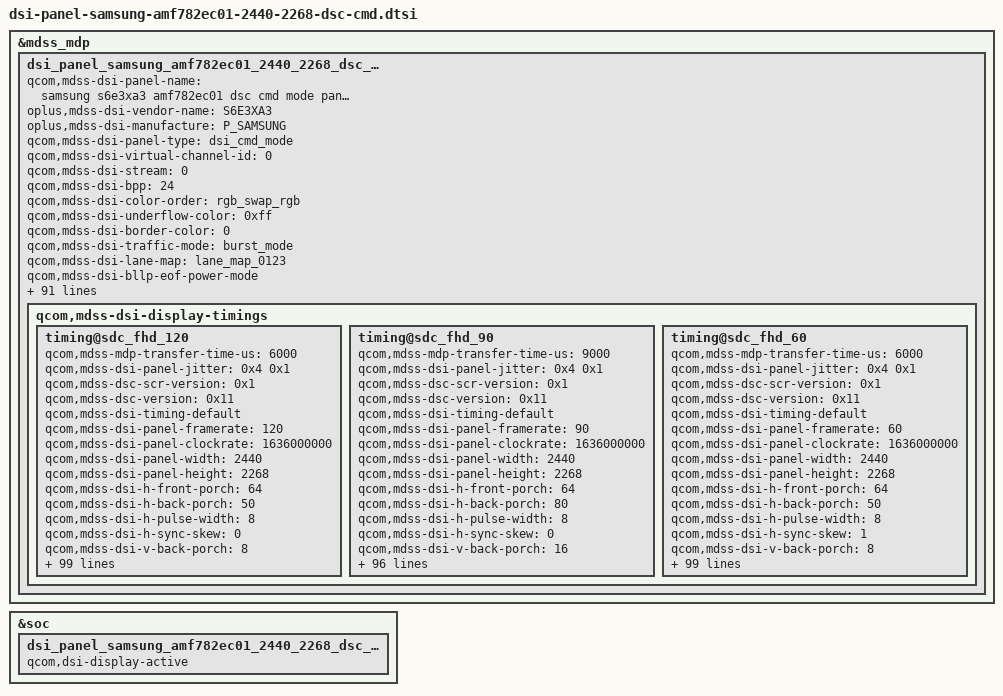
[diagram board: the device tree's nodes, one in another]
&mdss_mdp {
	dsi_panel_samsung_amf782ec01_2440_2268_dsc_cmd: qcom,mdss_dsi_panel_samsung_amf782ec01_2440_2268_dsc_cmd {
		qcom,mdss-dsi-panel-name = "samsung s6e3xa3 amf782ec01 dsc cmd mode panel";
		oplus,mdss-dsi-vendor-name = "S6E3XA3";
		oplus,mdss-dsi-manufacture = "P_SAMSUNG";
		qcom,mdss-dsi-panel-type = "dsi_cmd_mode";
		qcom,mdss-dsi-virtual-channel-id = <0>;
		qcom,mdss-dsi-stream = <0>;
		qcom,mdss-dsi-bpp = <24>;
		qcom,mdss-dsi-color-order = "rgb_swap_rgb";
		qcom,mdss-dsi-underflow-color = <0xff>;
		qcom,mdss-dsi-border-color = <0>;
		qcom,mdss-dsi-traffic-mode = "burst_mode";
		qcom,mdss-dsi-lane-map = "lane_map_0123";
		qcom,mdss-dsi-bllp-eof-power-mode;
		qcom,mdss-dsi-bllp-power-mode;
		qcom,mdss-dsi-lane-0-state;
		qcom,mdss-dsi-lane-1-state;
		qcom,mdss-dsi-lane-2-state;
		qcom,mdss-dsi-lane-3-state;
		qcom,mdss-dsi-dma-trigger = "trigger_sw";
		qcom,mdss-loading-effect;
		qcom,mdss-dsi-mdp-trigger = "none";
		qcom,mdss-dsi-reset-sequence = <1 10>, <0 5>, <1 10>;
		qcom,mdss-dsi-te-pin-select = <1>;
		qcom,mdss-dsi-te-dcs-command = <1>;
		qcom,mdss-pan-physical-width-dimension = <145>;
		qcom,mdss-pan-physical-height-dimension = <135>;
		qcom,mdss-dsi-init-delay-us = <1000>;
		qcom,mdss-dsi-te-check-enable;
		qcom,mdss-dsi-te-using-te-pin;
//		qcom,mdss-dsi-lp11-init;
		qcom,mdss-dsi-wr-mem-start = <0x2c>;
		qcom,mdss-dsi-wr-mem-continue = <0x3c>;
		qcom,mdss-dsi-panel-jitter = <0x4 0x1>;
		qcom,mdss-dsc-scr-version = <0x1>;
		qcom,mdss-bl-high2bit;
		/* HDR Setting */
		qcom,mdss-dsi-panel-hdr-enabled;
		qcom,mdss-dsi-panel-hdr-color-primaries = <15635 16450 34000 16000 13250 34500 7500 3000>;
		qcom,mdss-dsi-panel-peak-brightness = <5400000>;
		qcom,mdss-dsi-panel-average-brightness = <2000000>;
		qcom,mdss-dsi-panel-blackness-level = <4000>;
//		qcom,spr-pack-type = "pentile";

		qcom,dynamic-mode-switch-enabled;
		qcom,dynamic-mode-switch-type = "dynamic-resolution-switch-immediate";
		qcom,mdss-dsi-display-timings {
			timing@sdc_fhd_120{
				qcom,mdss-mdp-transfer-time-us = <6000>;
				qcom,mdss-dsi-panel-jitter = <0x4 0x1>;
				qcom,mdss-dsc-scr-version = <0x1>;
				qcom,mdss-dsc-version = <0x11>;
				qcom,mdss-dsi-timing-default;
				qcom,mdss-dsi-panel-framerate = <120>;
				qcom,mdss-dsi-panel-clockrate = <1636000000>;
				qcom,mdss-dsi-panel-width = <2440>;
				qcom,mdss-dsi-panel-height = <2268>;

				qcom,mdss-dsi-h-front-porch = <64>;
				qcom,mdss-dsi-h-back-porch = <50>;
				qcom,mdss-dsi-h-pulse-width = <8>;
				qcom,mdss-dsi-h-sync-skew = <0>;
				qcom,mdss-dsi-v-back-porch = <8>;
				qcom,mdss-dsi-v-front-porch = <2>;
				qcom,mdss-dsi-v-pulse-width = <2>;
				qcom,mdss-dsi-h-sync-pulse = <0>;

				qcom,mdss-dsi-h-left-border = <0>;
				qcom,mdss-dsi-h-right-border = <0>;
				qcom,mdss-dsi-v-top-border = <0>;
				qcom,mdss-dsi-v-bottom-border = <0>;

				/* Apollo vsync config, need to measure TE signal */
				//oplus,apollo-panel-vsync-width = <13000>;
				//oplus,apollo-panel-vsync-period = <16600>;

				oplus,fod-on-vblank = <0>;
				oplus,fod-off-vblank = <0>;
				//qcom,mdss-dsi-panel-read-register-open-command = [
				//	39 01 00 00 00 00 03 F0 5A 5A
				//	];
				qcom,mdss-dsi-panel-id1-command = [
					06 01 00 00 00 00 01 E9
					];
				//qcom,mdss-dsi-panel-read-register-close-command = [
				//	39 01 00 00 00 00 03 F0 A5 A5
				//	];
				qcom,mdss-dsi-timing-switch-command = [
					/*2c enable 3c disable*/
					39 00 00 40 00 00 03 F0 5A 5A
					39 00 00 40 00 00 04 B0 00 80 BD
					15 00 00 40 00 00 02 BD 16
					39 00 00 00 00 00 03 F0 A5 A5
					/*Frame rate=120Hz*/
					39 00 00 40 00 00 03 F0 5A 5A
					15 00 00 40 00 00 02 F2 01
					15 00 00 40 00 00 02 60 00
					15 00 00 40 00 00 02 F7 0F
					39 00 00 00 00 00 03 F0 A5 A5
					/*Manual 120Hz*/
					39 00 00 40 00 00 03 F0 5A 5A
					15 00 00 40 00 00 02 BD E1
					15 00 00 40 00 00 02 60 00
					15 00 00 40 00 00 02 F7 0F
					39 00 00 00 00 00 03 F0 A5 A5
					/*Fixed Te*/
					39 00 00 40 00 00 03 F0 5A 5A
					39 00 00 40 00 00 11 B9 51 41 00 00 00 00 00 00 08 F0 00 0F 08 F0 00 0F
					15 00 00 40 00 00 02 B9 51
					15 00 00 40 00 00 02 F7 0F
					39 00 00 00 00 00 03 F0 A5 A5
					/*Dynamic Single Te*/
					39 00 00 40 00 00 03 F0 5A 5A
					39 00 00 40 00 00 04 B0 00 44 F2
					15 00 00 40 00 00 02 F2 0D
					39 00 00 40 00 00 04 B0 00 01 B9
					15 00 00 40 00 00 02 B9 11
					15 00 00 40 00 00 02 F7 0F
					39 00 00 00 00 00 03 F0 A5 A5
					];
				qcom,mdss-dsi-on-command=[
					/*DSC Setting*/
					39 00 00 40 00 00 5A 9E 11 00 00 89 30 80 08 DC 09 88 00 3F 04 C4 04 C4 02 00 03 63 00 20 08 8B 00 10 00 0C 01 8D 00 B7 18 00 10 F0 03 0C 20 00 06 0B 0B 33 0E 1C 2A 38 46 54 62 69 70 77 79 7B 7D 7E 01 02 01 00 09 40 09 BE 19 FC 19 FA 19 F8 1A 38 1A 78 1A B6 2A F6 2B 34 2B 74 3B 74 6B F4 00
					15 00 00 00 00 00 02 9D 01
					/*sleep out*/
					05 00 00 00 78 00 01 11
					/*TE ON*/
					15 00 00 00 00 00 02 35 00
					/*CASET/PASET SETING*/
					39 00 00 40 00 00 05 2A 00 00 09 87
					39 00 00 00 00 00 05 2B 00 00 08 DB
					/*Pentile Setting*/
					39 00 00 40 00 00 03 F0 5A 5A
					39 00 00 40 00 00 04 B0 00 A2 92
					39 00 00 40 00 00 07 92 0A 0A D8 D8 C0 C0
					15 00 00 40 00 00 02 F7 0F
					39 00 00 00 00 00 03 F0 A5 A5
					/* ERR_FG_Setting */
					39 00 00 40 00 00 03 F0 5A 5A
					15 00 00 40 00 00 02 E5 15
					39 00 00 40 00 00 04 B0 00 02 ED
					15 00 00 40 00 00 02 ED 60
					39 00 00 40 00 00 04 B0 00 59 F4
					15 00 00 40 00 00 02 F4 10
					39 00 00 40 00 00 03 ED 00 51
					39 00 00 00 00 00 03 F0 A5 A5
					/*Dimming Setting*/
					39 00 00 40 00 00 03 F0 5A 5A
					15 00 00 40 00 00 02 53 20
					15 00 00 40 00 00 02 F7 0F
					39 00 00 00 00 00 03 F0 A5 A5
					/*2c enable 3c disable*/
					39 00 00 40 00 00 03 F0 5A 5A
					39 00 00 40 00 00 04 B0 00 80 BD
					15 00 00 40 00 00 02 BD 16
					39 00 00 00 00 00 03 F0 A5 A5
					/*Frame rate=120Hz*/
					39 00 00 40 00 00 03 F0 5A 5A
					15 00 00 40 00 00 02 F2 01
					15 00 00 40 00 00 02 60 00
					15 00 00 40 00 00 02 F7 0F
					39 00 00 00 00 00 03 F0 A5 A5
					/*Manual 120Hz*/
					39 00 00 40 00 00 03 F0 5A 5A
					15 00 00 40 00 00 02 BD E1
					15 00 00 40 00 00 02 60 00
					15 00 00 40 00 00 02 F7 0F
					39 00 00 00 00 00 03 F0 A5 A5
					/*Fixed Te*/
					39 00 00 40 00 00 03 F0 5A 5A
					39 00 00 40 00 00 11 B9 51 41 00 00 00 00 00 00 08 F0 00 0F 08 F0 00 0F
					15 00 00 40 00 00 02 B9 51
					15 00 00 40 00 00 02 F7 0F
					39 00 00 00 00 00 03 F0 A5 A5
					/*Dynamic Single Te*/
					39 00 00 40 00 00 03 F0 5A 5A
					39 00 00 40 00 00 04 B0 00 44 F2
					15 00 00 40 00 00 02 F2 0D
					39 00 00 40 00 00 04 B0 00 01 B9
					15 00 00 40 00 00 02 B9 11
					15 00 00 40 00 00 02 F7 0F
					39 00 00 00 00 00 03 F0 A5 A5
					/*display on*/
					05 00 00 00 00 00 01 29
				];

				qcom,mdss-dsi-panel-info-switch-page-command = [
					/*read panel info switch page 01*/
					39 00 00 00 00 00 06 F0 55 AA 52 08 01
				];
				qcom,mdss-dsi-default-switch-page-command = [
					/*switch default page*/
					39 00 00 00 00 00 06 F0 55 AA 52 08 00
				];
				qcom,mdss-dsi-qsync-on-commands = [
					/* SDC Auto On */
				];
				qcom,mdss-dsi-qsync-off-commands = [
					/* SDC Auto Off */
				];
				qcom,mdss-dsi-qsync-min-fps-0-command = [
					/* SDC Auto Off */
					39 00 00 40 00 00 03 F0 5A 5A
					15 00 00 40 00 00 02 BD E1
					15 00 00 40 00 00 02 60 00
					15 00 00 40 00 00 02 F7 0F
					39 00 00 00 00 00 03 F0 A5 A5
				];
				qcom,mdss-dsi-qsync-min-fps-1-command = [
					/* SDC Auto On */
				];

				qcom,mdss-dsi-post-on-backlight = [
					/* Display On */
					05 00 00 00 00 00 01 29
				];
				qcom,mdss-dsi-off-command=[
					05 00 00 00 14 00 01 28
					05 00 00 00 78 00 01 10
				];
				qcom,mdss-dsi-lp1-command = [
					/* Panel OFF */
					05 00 00 00 09 00 01 28
					/* AOD Mode ON Setting */
					39 00 00 40 00 00 03 F0 5A 5A
					39 00 00 40 00 00 04 B0 00 52 64
					39 00 00 40 00 00 07 64 01 03 29 0B 03 2A
					15 00 00 40 00 00 02 53 24
					39 00 00 40 00 00 03 51 07 FF
					15 00 00 40 00 00 02 F7 0F
					39 00 00 00 00 00 03 F0 A5 A5
				];
				qcom,mdss-dsi-nolp-command = [
					/* Panel OFF */
					05 00 00 00 00 00 01 28
					/* AOD Mode OFF Setting */
					39 00 00 40 00 00 03 F0 5A 5A
					39 00 00 40 00 00 04 B0 00 52 64
					15 00 00 40 00 00 02 64 00
					15 00 00 40 00 00 02 53 20
					39 00 00 40 00 00 03 51 00 00
					15 00 00 40 00 00 02 F7 0F
					39 00 00 00 22 00 03 F0 A5 A5
					/* Panel ON */
					05 00 00 00 00 00 01 29
				];
				qcom,mdss-dsi-hbm-off-command = [
					39 00 00 40 00 00 03 F0 5A 5A
					39 00 00 40 00 00 03 51 08 00
					39 00 00 00 00 00 03 F0 A5 A5
				];
				qcom,mdss-dsi-hbm-on-command = [
					39 00 00 40 00 00 03 F0 5A 5A
					39 00 00 40 00 00 03 51 0F 00
					39 00 00 00 00 00 03 F0 A5 A5
				];
				qcom,mdss-dsi-aod-high-mode-command = [
					/* AOD 50nit */
					15 00 00 40 00 00 02 6F 04
					39 00 00 00 00 00 03 51 07 FF
				];
				qcom,mdss-dsi-aod-low-mode-command = [
					/* AOD 10nit */
					15 00 00 40 00 00 02 6F 04
					39 00 00 00 00 00 03 51 03 8A
				];
				//qcom,mdss-dsi-esd-switch-page-command = [
				//	39 00 00 00 00 00 05 FF AA 55 A5 81
				//	15 00 00 00 00 00 02 6F 0F
				//];
				qcom,mdss-dsi-bl-3plus-command = [
					/*3plus 51Hey > 0x643*/
				];
				qcom,mdss-dsi-bl-16plus-command = [
					/*16plus 51Hey <= 0x643*/
				];
				qcom,mdss-dsi-temperature-compensation-command = [
				];
				qcom,mdss-dsi-loading-effect-1-command = [
					/* Laoding On 100% */
					39 00 00 40 00 00 03 F0 5A 5A
					39 00 00 40 00 00 04 B0 00 AF 93
					15 00 00 40 00 00 02 93 A3
					39 00 00 40 00 00 04 B0 00 B0 93
					39 00 00 40 00 00 27 93 FC 0B 92 80 01 FF 00 8C FF 00 FF 35 58 6D 06 06 05 18 19 16 20 22 1E 26 28 24 29 2B 26 3D 8D 86 E8 20 00 00 08 54
					39 00 00 40 00 00 04 B0 00 39 94
					39 00 00 40 00 00 27 94 E2 00 00 00 82 46 24 80 00 00 00 00 FF 90 00 00 01 00 00 00 00 00 00 00 00 00 00 00 00 00 00 00 00 00 00 00 00 00
					39 00 00 40 00 00 04 B0 00 41 94
					39 00 00 40 00 00 07 94 00 00 00 00 FF 90
					39 00 00 00 00 00 03 F0 A5 A5
				];
				qcom,mdss-dsi-loading-effect-2-command = [
					/* Laoding On 110% */
					39 00 00 40 00 00 03 F0 5A 5A
					39 00 00 40 00 00 04 B0 00 AF 93
					15 00 00 40 00 00 02 93 A3
					39 00 00 40 00 00 04 B0 00 B0 93
					39 00 00 40 00 00 27 93 FC 0B 92 80 01 FF 00 8C FF 00 FF 35 58 6D 06 06 05 18 19 16 20 22 1E 26 28 24 29 2B 26 3D 8D 86 E8 20 00 00 08 54
					39 00 00 40 00 00 04 B0 00 39 94
					39 00 00 40 00 00 27 94 E2 00 00 00 82 46 24 80 00 00 00 00 FF 90 00 00 01 00 00 00 00 00 00 00 00 00 00 00 00 00 00 00 00 00 00 00 00 00
					39 00 00 40 00 00 04 B0 00 41 94
					39 00 00 40 00 00 07 94 9B 7C 7C 63 FF 90
					39 00 00 00 00 00 03 F0 A5 A5
				];
				qcom,mdss-dsi-loading-effect-3-command = [
				];
				qcom,mdss-dsi-loading-effect-4-command = [
				];
				qcom,mdss-dsi-loading-effect-off-command = [
					39 00 00 40 00 00 03 F0 5A 5A
					39 00 00 40 00 00 04 B0 00 AF 93
					15 00 00 40 00 00 02 93 83
					39 00 00 00 00 00 03 F0 A5 A5
				];
				qcom,mdss-dsi-loading-effect-1-command-state = "dsi_hs_mode";
				qcom,mdss-dsi-loading-effect-2-command-state = "dsi_hs_mode";
				qcom,mdss-dsi-loading-effect-3-command-state = "dsi_hs_mode";
				qcom,mdss-dsi-loading-effect-4-command-state = "dsi_hs_mode";
				qcom,mdss-dsi-loading-effect-off-command-state = "dsi_hs_mode";
				qcom,mdss-dsi-timing-switch-command-state = "dsi_hs_mode";
				qcom,mdss-dsi-on-command-state = "dsi_lp_mode";
				qcom,mdss-dsi-off-command-state = "dsi_hs_mode";
				qcom,mdss-dsi-hbm-on-command-state = "dsi_lp_mode";
				qcom,mdss-dsi-hbm-off-command-state = "dsi_lp_mode";
				qcom,mdss-dsi-bl-16plus-command-state = "dsi_hs_mode";
				qcom,mdss-dsi-bl-3plus-command-state = "dsi_hs_mode";
				qcom,mdss-dsi-temperature-compensation-command-state = "dsi_hs_mode";
				qcom,mdss-dsi-panel-info-switch-page-command-state = "dsi_lp_mode";
				qcom,mdss-dsi-default-switch-page-command-state = "dsi_lp_mode";

				qcom,mdss-dsi-qsync-min-fps-0-command-state = "dsi_hs_mode";
				qcom,mdss-dsi-qsync-min-fps-1-command-state = "dsi_hs_mode";

				qcom,lm-split = <1220 1220>;
				qcom,compression-mode = "dsc";
				qcom,mdss-dsc-encoders = <2>;
				qcom,mdss-dsc-slice-height = <63>;
				qcom,mdss-dsc-slice-width = <1220>;
				qcom,mdss-dsc-slice-per-pkt = <2>;
				qcom,mdss-dsc-bit-per-component = <8>;
				qcom,mdss-dsc-bit-per-pixel = <8>;
				qcom,mdss-dsc-block-prediction-enable;
				qcom,mdss-dsi-panel-id1-command-state = "dsi_lp_mode";
			};
			timing@sdc_fhd_90{
				qcom,mdss-mdp-transfer-time-us = <9000>;
				qcom,mdss-dsi-panel-jitter = <0x4 0x1>;
				qcom,mdss-dsc-scr-version = <0x1>;
				qcom,mdss-dsc-version = <0x11>;
				qcom,mdss-dsi-timing-default;
				qcom,mdss-dsi-panel-framerate = <90>;
				qcom,mdss-dsi-panel-clockrate = <1636000000>;
				qcom,mdss-dsi-panel-width = <2440>;
				qcom,mdss-dsi-panel-height = <2268>;

				qcom,mdss-dsi-h-front-porch = <64>;
				qcom,mdss-dsi-h-back-porch = <80>;
				qcom,mdss-dsi-h-pulse-width = <8>;
				qcom,mdss-dsi-h-sync-skew = <0>;
				qcom,mdss-dsi-v-back-porch = <16>;
				qcom,mdss-dsi-v-front-porch = <10>;
				qcom,mdss-dsi-v-pulse-width = <2>;
				qcom,mdss-dsi-h-sync-pulse = <0>;

				qcom,mdss-dsi-h-left-border = <0>;
				qcom,mdss-dsi-h-right-border = <0>;
				qcom,mdss-dsi-v-top-border = <0>;
				qcom,mdss-dsi-v-bottom-border = <0>;

				/* Apollo vsync config, need to measure TE signal */
				//oplus,apollo-panel-vsync-width = <13000>;
				//oplus,apollo-panel-vsync-period = <16600>;

				oplus,fod-on-vblank = <0>;
				oplus,fod-off-vblank = <0>;
				//qcom,mdss-dsi-panel-read-register-open-command = [
				//	39 00 00 00 00 00 03 F0 5A 5A
				//	];
				qcom,mdss-dsi-panel-id1-command = [
					06 00 00 00 00 00 01 E9
					];
				//qcom,mdss-dsi-panel-read-register-close-command = [
				//	39 00 00 00 00 00 03 F0 A5 A5
				//	];
				qcom,mdss-dsi-timing-switch-command = [
					/* Frequence Transition */
					39 00 00 40 00 00 03 F0 5A 5A
					15 00 00 40 00 00 02 B9 11
					15 00 00 40 00 00 02 F2 01
					15 00 00 40 00 00 02 60 10
					15 00 00 40 00 00 02 F7 0F
					39 00 00 00 00 00 03 F0 A5 A5
					];
				qcom,mdss-dsi-on-command=[
					/*DSC Setting*/
					39 00 00 40 00 00 5A 9E 11 00 00 89 30 80 08 DC 09 88 00 3F 04 C4 04 C4 02 00 03 63 00 20 08 8B 00 10 00 0C 01 8D 00 B7 18 00 10 F0 03 0C 20 00 06 0B 0B 33 0E 1C 2A 38 46 54 62 69 70 77 79 7B 7D 7E 01 02 01 00 09 40 09 BE 19 FC 19 FA 19 F8 1A 38 1A 78 1A B6 2A F6 2B 34 2B 74 3B 74 6B F4 00
					15 00 00 00 00 00 02 9D 01
					/*sleep out*/
					05 00 00 00 78 00 01 11
					/*TE ON*/
					15 00 00 00 00 00 02 35 00
					/*CASET/PASET SETING*/
					39 00 00 40 00 00 05 2A 00 00 09 87
					39 00 00 00 00 00 05 2B 00 00 08 DB
					/*Pentile Setting*/
					39 00 00 40 00 00 03 F0 5A 5A
					39 00 00 40 00 00 04 B0 00 A2 92
					39 00 00 40 00 00 07 92 0A 0A D8 D8 C0 C0
					15 00 00 40 00 00 02 F7 0F
					39 00 00 00 00 00 03 F0 A5 A5
					/* ERR_FG_Setting */
					39 00 00 40 00 00 03 F0 5A 5A
					15 00 00 40 00 00 02 E5 15
					39 00 00 40 00 00 04 B0 00 02 ED
					15 00 00 40 00 00 02 ED 60
					39 00 00 40 00 00 04 B0 00 59 F4
					15 00 00 40 00 00 02 F4 10
					39 00 00 40 00 00 03 ED 00 51
					39 00 00 00 00 00 03 F0 A5 A5
					/*Dimming Setting*/
					39 00 00 40 00 00 03 F0 5A 5A
					15 00 00 40 00 00 02 53 20
					15 00 00 40 00 00 02 F7 0F
					39 00 00 00 00 00 03 F0 A5 A5
					/*Frame rate=90Hz*/
					39 00 00 40 00 00 03 F0 5A 5A
					15 00 00 40 00 00 02 B9 11
					15 00 00 40 00 00 02 F2 01
					15 00 00 40 00 00 02 60 10
					15 00 00 40 00 00 02 F7 0F
					39 00 00 00 00 00 03 F0 A5 A5
					/*display on*/
					05 00 00 00 00 00 01 29
				];

				qcom,mdss-dsi-panel-info-switch-page-command = [
					/*read panel info switch page 01*/
					39 00 00 00 00 00 06 F0 55 AA 52 08 01
				];
				qcom,mdss-dsi-default-switch-page-command = [
					/*switch default page*/
					39 00 00 00 00 00 06 F0 55 AA 52 08 00
				];
				qcom,mdss-dsi-qsync-on-commands = [
					/* SDC Auto On */
				];
				qcom,mdss-dsi-qsync-off-commands = [
					/* SDC Auto Off */
				];
				qcom,mdss-dsi-qsync-min-fps-0-command = [
					/* SDC Auto Off */
				];
				qcom,mdss-dsi-qsync-min-fps-1-command = [
					/* SDC Auto On */
				];

				qcom,mdss-dsi-post-on-backlight = [
					/* Display On */
					05 00 00 00 00 00 01 29
				];
				qcom,mdss-dsi-off-command=[
					05 00 00 00 14 00 01 28
					05 00 00 00 78 00 01 10
				];
				qcom,mdss-dsi-lp1-command = [
					/* Panel OFF */
					05 00 00 00 0B 00 01 28
					/* AOD Mode ON Setting */
					39 00 00 40 00 00 03 F0 5A 5A
					39 00 00 40 00 00 04 B0 00 52 64
					39 00 00 40 00 00 07 64 01 03 29 0B 03 2A
					15 00 00 40 00 00 02 53 24
					39 00 00 40 00 00 03 51 07 FF
					15 00 00 40 00 00 02 F7 0F
					39 00 00 00 00 00 03 F0 A5 A5
				];
				qcom,mdss-dsi-nolp-command = [
					/* Panel OFF */
					05 00 00 00 00 00 01 28
					/* AOD Mode OFF Setting */
					39 00 00 40 00 00 03 F0 5A 5A
					39 00 00 40 00 00 04 B0 00 52 64
					15 00 00 40 00 00 02 64 00
					15 00 00 40 00 00 02 53 20
					39 00 00 40 00 00 03 51 00 00
					15 00 00 40 00 00 02 F7 0F
					39 00 00 00 22 00 03 F0 A5 A5
					/* Panel ON */
					05 00 00 00 00 00 01 29
				];
				qcom,mdss-dsi-hbm-off-command = [
					39 00 00 40 00 00 03 F0 5A 5A
					39 00 00 40 00 00 03 51 08 00
					39 00 00 00 00 00 03 F0 A5 A5
				];
				qcom,mdss-dsi-hbm-on-command = [
					39 00 00 40 00 00 03 F0 5A 5A
					39 00 00 40 00 00 03 51 0F 00
					39 00 00 00 00 00 03 F0 A5 A5
				];
				qcom,mdss-dsi-aod-high-mode-command = [
					/* AOD 50nit */
					15 00 00 40 00 00 02 6F 04
					39 00 00 00 00 00 03 51 07 FF
				];
				qcom,mdss-dsi-aod-low-mode-command = [
					/* AOD 10nit */
					15 00 00 40 00 00 02 6F 04
					39 00 00 00 00 00 03 51 03 8A
				];
				//qcom,mdss-dsi-esd-switch-page-command = [
				//	39 00 00 00 00 00 05 FF AA 55 A5 81
				//	15 00 00 00 00 00 02 6F 0F
				//];
				qcom,mdss-dsi-bl-3plus-command = [
					/*3plus 51Hey > 0x643*/
					39 00 00 00 00 00 06 F0 55 AA 52 08 00
					39 00 00 00 00 00 02 6F 12
					39 00 00 00 00 00 02 B2 03
				];
				qcom,mdss-dsi-bl-16plus-command = [
					/*16plus 51Hey <= 0x643*/
					39 00 00 00 00 00 06 F0 55 AA 52 08 00
					39 00 00 00 00 00 02 6F 12
					39 00 00 00 00 00 02 B2 0F
				];
				qcom,mdss-dsi-temperature-compensation-command = [
				];
				qcom,mdss-dsi-loading-effect-1-command = [
					/* Laoding On 100% */
					39 00 00 40 00 00 03 F0 5A 5A
					39 00 00 40 00 00 04 B0 00 AF 93
					15 00 00 40 00 00 02 93 A3
					39 00 00 40 00 00 04 B0 00 B0 93
					39 00 00 40 00 00 27 93 FC 0B 92 80 01 FF 00 8C FF 00 FF 35 58 6D 06 06 05 18 19 16 20 22 1E 26 28 24 29 2B 26 3D 8D 86 E8 20 00 00 08 54
					39 00 00 40 00 00 04 B0 00 39 94
					39 00 00 40 00 00 27 94 E2 00 00 00 82 46 24 80 00 00 00 00 FF 90 00 00 01 00 00 00 00 00 00 00 00 00 00 00 00 00 00 00 00 00 00 00 00 00
					39 00 00 40 00 00 04 B0 00 41 94
					39 00 00 40 00 00 07 94 00 00 00 00 FF 90
					39 00 00 00 00 00 03 F0 A5 A5
				];
				qcom,mdss-dsi-loading-effect-2-command = [
					/* Laoding On 110% */
					39 00 00 40 00 00 03 F0 5A 5A
					39 00 00 40 00 00 04 B0 00 AF 93
					15 00 00 40 00 00 02 93 A3
					39 00 00 40 00 00 04 B0 00 B0 93
					39 00 00 40 00 00 27 93 FC 0B 92 80 01 FF 00 8C FF 00 FF 35 58 6D 06 06 05 18 19 16 20 22 1E 26 28 24 29 2B 26 3D 8D 86 E8 20 00 00 08 54
					39 00 00 40 00 00 04 B0 00 39 94
					39 00 00 40 00 00 27 94 E2 00 00 00 82 46 24 80 00 00 00 00 FF 90 00 00 01 00 00 00 00 00 00 00 00 00 00 00 00 00 00 00 00 00 00 00 00 00
					39 00 00 40 00 00 04 B0 00 41 94
					39 00 00 40 00 00 07 94 9B 7C 7C 63 FF 90
					39 00 00 00 00 00 03 F0 A5 A5
				];
				qcom,mdss-dsi-loading-effect-3-command = [
				];
				qcom,mdss-dsi-loading-effect-4-command = [
				];
				qcom,mdss-dsi-loading-effect-off-command = [
					39 00 00 40 00 00 03 F0 5A 5A
					39 00 00 40 00 00 04 B0 00 AF 93
					15 00 00 40 00 00 02 93 83
					39 00 00 00 00 00 03 F0 A5 A5
				];
				qcom,mdss-dsi-loading-effect-1-command-state = "dsi_hs_mode";
				qcom,mdss-dsi-loading-effect-2-command-state = "dsi_hs_mode";
				qcom,mdss-dsi-loading-effect-3-command-state = "dsi_hs_mode";
				qcom,mdss-dsi-loading-effect-4-command-state = "dsi_hs_mode";
				qcom,mdss-dsi-loading-effect-off-command-state = "dsi_hs_mode";
				qcom,mdss-dsi-timing-switch-command-state = "dsi_hs_mode";
				qcom,mdss-dsi-on-command-state = "dsi_lp_mode";
				qcom,mdss-dsi-off-command-state = "dsi_hs_mode";
				qcom,mdss-dsi-hbm-on-command-state = "dsi_lp_mode";
				qcom,mdss-dsi-hbm-off-command-state = "dsi_lp_mode";
				qcom,mdss-dsi-bl-16plus-command-state = "dsi_hs_mode";
				qcom,mdss-dsi-bl-3plus-command-state = "dsi_hs_mode";
				qcom,mdss-dsi-temperature-compensation-command-state = "dsi_hs_mode";
				qcom,mdss-dsi-panel-info-switch-page-command-state = "dsi_lp_mode";
				qcom,mdss-dsi-default-switch-page-command-state = "dsi_lp_mode";

				qcom,lm-split = <1220 1220>;
				qcom,compression-mode = "dsc";
				qcom,mdss-dsc-encoders = <2>;
				qcom,mdss-dsc-slice-height = <63>;
				qcom,mdss-dsc-slice-width = <1220>;
				qcom,mdss-dsc-slice-per-pkt = <2>;
				qcom,mdss-dsc-bit-per-component = <8>;
				qcom,mdss-dsc-bit-per-pixel = <8>;
				qcom,mdss-dsc-block-prediction-enable;
				qcom,mdss-dsi-panel-id1-command-state = "dsi_lp_mode";
			};
			timing@sdc_fhd_60{
				qcom,mdss-mdp-transfer-time-us = <6000>;
				qcom,mdss-dsi-panel-jitter = <0x4 0x1>;
				qcom,mdss-dsc-scr-version = <0x1>;
				qcom,mdss-dsc-version = <0x11>;
				qcom,mdss-dsi-timing-default;
				qcom,mdss-dsi-panel-framerate = <60>;
				qcom,mdss-dsi-panel-clockrate = <1636000000>;
				qcom,mdss-dsi-panel-width = <2440>;
				qcom,mdss-dsi-panel-height = <2268>;

				qcom,mdss-dsi-h-front-porch = <64>;
				qcom,mdss-dsi-h-back-porch = <50>;
				qcom,mdss-dsi-h-pulse-width = <8>;
				qcom,mdss-dsi-h-sync-skew = <1>;
				qcom,mdss-dsi-v-back-porch = <8>;
				qcom,mdss-dsi-v-front-porch = <2>;
				qcom,mdss-dsi-v-pulse-width = <2>;
				qcom,mdss-dsi-h-sync-pulse = <0>;

				qcom,mdss-dsi-h-left-border = <0>;
				qcom,mdss-dsi-h-right-border = <0>;
				qcom,mdss-dsi-v-top-border = <0>;
				qcom,mdss-dsi-v-bottom-border = <0>;

				/* Apollo vsync config, need to measure TE signal */
				//oplus,apollo-panel-vsync-width = <13000>;
				//oplus,apollo-panel-vsync-period = <16600>;

				oplus,fod-on-vblank = <0>;
				oplus,fod-off-vblank = <0>;
				//qcom,mdss-dsi-panel-read-register-open-command = [
				//	39 01 00 00 00 00 03 F0 5A 5A
				//	];
				qcom,mdss-dsi-panel-id1-command = [
					06 01 00 00 00 00 01 E9
					];
				//qcom,mdss-dsi-panel-read-register-close-command = [
				//	39 01 00 00 00 00 03 F0 A5 A5
				//	];
				qcom,mdss-dsi-timing-switch-command = [
					/*2c enable 3c disable*/
					39 00 00 40 00 00 03 F0 5A 5A
					39 00 00 40 00 00 04 B0 00 80 BD
					15 00 00 40 00 00 02 BD 16
					39 00 00 00 00 00 03 F0 A5 A5
					/*Manual 60Hz*/
					39 00 00 40 00 00 03 F0 5A 5A
					15 00 00 40 00 00 02 F2 01
					15 00 00 40 00 00 02 60 00
					15 00 00 40 00 00 02 BD E1
					15 00 00 40 00 00 02 60 01
					15 00 00 40 00 00 02 F7 0F
					39 00 00 00 00 00 03 F0 A5 A5
					/*Fixed Te 60HZ*/
					39 00 00 40 00 00 03 F0 5A 5A
					39 00 00 40 00 00 11 B9 51 41 01 00 00 00 00 00 08 F0 00 0F 08 F0 00 0F
					15 00 00 40 00 00 02 B9 51
					15 00 00 40 00 00 02 F7 0F
					39 00 00 00 00 00 03 F0 A5 A5
					/*Dynamic Single Te*/
					39 00 00 40 00 00 03 F0 5A 5A
					39 00 00 40 00 00 04 B0 00 44 F2
					15 00 00 40 00 00 02 F2 0D
					39 00 00 40 00 00 04 B0 00 01 B9
					15 00 00 40 00 00 02 B9 11
					15 00 00 40 00 00 02 F7 0F
					39 00 00 00 00 00 03 F0 A5 A5
				];
				qcom,mdss-dsi-on-command=[
					/*DSC Setting*/
					39 00 00 40 00 00 5A 9E 11 00 00 89 30 80 08 DC 09 88 00 3F 04 C4 04 C4 02 00 03 63 00 20 08 8B 00 10 00 0C 01 8D 00 B7 18 00 10 F0 03 0C 20 00 06 0B 0B 33 0E 1C 2A 38 46 54 62 69 70 77 79 7B 7D 7E 01 02 01 00 09 40 09 BE 19 FC 19 FA 19 F8 1A 38 1A 78 1A B6 2A F6 2B 34 2B 74 3B 74 6B F4 00
					15 00 00 00 00 00 02 9D 01
					/*sleep out*/
					05 00 00 00 78 00 01 11
					/*TE ON*/
					15 00 00 00 00 00 02 35 00
					/*CASET/PASET SETING*/
					39 00 00 40 00 00 05 2A 00 00 09 87
					39 00 00 00 00 00 05 2B 00 00 08 DB
					/*Pentile Setting*/
					39 00 00 40 00 00 03 F0 5A 5A
					39 00 00 40 00 00 04 B0 00 A2 92
					39 00 00 40 00 00 07 92 0A 0A D8 D8 C0 C0
					15 00 00 40 00 00 02 F7 0F
					39 00 00 00 00 00 03 F0 A5 A5
					/* ERR_FG_Setting */
					39 00 00 40 00 00 03 F0 5A 5A
					15 00 00 40 00 00 02 E5 15
					39 00 00 40 00 00 04 B0 00 02 ED
					15 00 00 40 00 00 02 ED 60
					39 00 00 40 00 00 04 B0 00 59 F4
					15 00 00 40 00 00 02 F4 10
					39 00 00 40 00 00 03 ED 00 51
					39 00 00 00 00 00 03 F0 A5 A5
					/*Dimming Setting*/
					39 00 00 40 00 00 03 F0 5A 5A
					15 00 00 40 00 00 02 53 20
					15 00 00 40 00 00 02 F7 0F
					39 00 00 00 00 00 03 F0 A5 A5
					/*2c enable 3c disable*/
					39 00 00 40 00 00 03 F0 5A 5A
					39 00 00 40 00 00 04 B0 00 80 BD
					15 00 00 40 00 00 02 BD 16
					39 00 00 00 00 00 03 F0 A5 A5
					/*Manual 60Hz*/
					39 00 00 40 00 00 03 F0 5A 5A
					15 00 00 40 00 00 02 F2 01
					15 00 00 40 00 00 02 60 00
					15 00 00 40 00 00 02 BD E1
					15 00 00 40 00 00 02 60 01
					15 00 00 40 00 00 02 F7 0F
					39 00 00 00 00 00 03 F0 A5 A5
					/*Fixed Te 60HZ*/
					39 00 00 40 00 00 03 F0 5A 5A
					39 00 00 40 00 00 11 B9 51 41 01 00 00 00 00 00 08 F0 00 0F 08 F0 00 0F
					15 00 00 40 00 00 02 B9 51
					15 00 00 40 00 00 02 F7 0F
					39 00 00 00 00 00 03 F0 A5 A5
					/*Dynamic Single Te*/
					39 00 00 40 00 00 03 F0 5A 5A
					39 00 00 40 00 00 04 B0 00 44 F2
					15 00 00 40 00 00 02 F2 0D
					39 00 00 40 00 00 04 B0 00 01 B9
					15 00 00 40 00 00 02 B9 11
					15 00 00 40 00 00 02 F7 0F
					39 00 00 00 00 00 03 F0 A5 A5
					/*display on*/
					05 00 00 00 00 00 01 29
				];

				qcom,mdss-dsi-panel-info-switch-page-command = [
					/*read panel info switch page 01*/
					39 00 00 00 00 00 06 F0 55 AA 52 08 01
				];
				qcom,mdss-dsi-default-switch-page-command = [
					/*switch default page*/
					39 00 00 00 00 00 06 F0 55 AA 52 08 00
				];
				qcom,mdss-dsi-qsync-on-commands = [
					/* SDC Auto On */
				];
				qcom,mdss-dsi-qsync-off-commands = [
					/* SDC Auto Off */
				];
				qcom,mdss-dsi-qsync-min-fps-0-command = [
					/* SDC Auto Off */
					39 00 00 40 00 00 03 F0 5A 5A
					15 00 00 40 00 00 02 BD E1
					15 00 00 40 00 00 02 60 01
					15 00 00 40 00 00 02 F7 0F
					39 00 00 00 00 00 03 F0 A5 A5
				];
				qcom,mdss-dsi-qsync-min-fps-1-command = [
					/* SDC Auto On */
				];

				qcom,mdss-dsi-post-on-backlight = [
					/* Display On */
					05 00 00 00 00 00 01 29
				];
				qcom,mdss-dsi-off-command=[
					05 00 00 00 14 00 01 28
					05 00 00 00 78 00 01 10
				];
				qcom,mdss-dsi-lp1-command = [
					/* Panel OFF */
					05 00 00 00 09 00 01 28
					/* AOD Mode ON Setting */
					39 00 00 40 00 00 03 F0 5A 5A
					39 00 00 40 00 00 04 B0 00 52 64
					39 00 00 40 00 00 07 64 01 03 29 0B 03 2A
					15 00 00 40 00 00 02 53 24
					39 00 00 40 00 00 03 51 07 FF
					15 00 00 40 00 00 02 F7 0F
					39 00 00 00 00 00 03 F0 A5 A5
				];
				qcom,mdss-dsi-nolp-command = [
					/* Panel OFF */
					05 00 00 00 00 00 01 28
					/* AOD Mode OFF Setting */
					39 00 00 40 00 00 03 F0 5A 5A
					39 00 00 40 00 00 04 B0 00 52 64
					15 00 00 40 00 00 02 64 00
					15 00 00 40 00 00 02 53 20
					39 00 00 40 00 00 03 51 00 00
					15 00 00 40 00 00 02 F7 0F
					39 00 00 00 22 00 03 F0 A5 A5
					/* Panel ON */
					05 00 00 00 00 00 01 29
				];
				qcom,mdss-dsi-hbm-off-command = [
					39 00 00 40 00 00 03 F0 5A 5A
					39 00 00 40 00 00 03 51 08 00
					39 00 00 00 00 00 03 F0 A5 A5
				];
				qcom,mdss-dsi-hbm-on-command = [
					39 00 00 40 00 00 03 F0 5A 5A
					39 00 00 40 00 00 03 51 0F 00
					39 00 00 00 00 00 03 F0 A5 A5
				];
				qcom,mdss-dsi-aod-high-mode-command = [
					/* AOD 50nit */
					15 00 00 40 00 00 02 6F 04
					39 00 00 00 00 00 03 51 07 FF
				];
				qcom,mdss-dsi-aod-low-mode-command = [
					/* AOD 10nit */
					15 00 00 40 00 00 02 6F 04
					39 00 00 00 00 00 03 51 03 8A
				];
				//qcom,mdss-dsi-esd-switch-page-command = [
				//	39 00 00 00 00 00 05 FF AA 55 A5 81
				//	15 00 00 00 00 00 02 6F 0F
				//];
				qcom,mdss-dsi-bl-3plus-command = [
					/*3plus 51Hey > 0x643*/
				];
				qcom,mdss-dsi-bl-16plus-command = [
					/*16plus 51Hey <= 0x643*/
				];
				qcom,mdss-dsi-temperature-compensation-command = [
				];
				qcom,mdss-dsi-loading-effect-1-command = [
					/* Laoding On 100% */
					39 00 00 40 00 00 03 F0 5A 5A
					39 00 00 40 00 00 04 B0 00 AF 93
					15 00 00 40 00 00 02 93 A3
					39 00 00 40 00 00 04 B0 00 B0 93
					39 00 00 40 00 00 27 93 FC 0B 92 80 01 FF 00 8C FF 00 FF 35 58 6D 06 06 05 18 19 16 20 22 1E 26 28 24 29 2B 26 3D 8D 86 E8 20 00 00 08 54
					39 00 00 40 00 00 04 B0 00 39 94
					39 00 00 40 00 00 27 94 E2 00 00 00 82 46 24 80 00 00 00 00 FF 90 00 00 01 00 00 00 00 00 00 00 00 00 00 00 00 00 00 00 00 00 00 00 00 00
					39 00 00 40 00 00 04 B0 00 41 94
					39 00 00 40 00 00 07 94 00 00 00 00 FF 90
					39 00 00 00 00 00 03 F0 A5 A5
				];
				qcom,mdss-dsi-loading-effect-2-command = [
					/* Laoding On 110% */
					39 00 00 40 00 00 03 F0 5A 5A
					39 00 00 40 00 00 04 B0 00 AF 93
					15 00 00 40 00 00 02 93 A3
					39 00 00 40 00 00 04 B0 00 B0 93
					39 00 00 40 00 00 27 93 FC 0B 92 80 01 FF 00 8C FF 00 FF 35 58 6D 06 06 05 18 19 16 20 22 1E 26 28 24 29 2B 26 3D 8D 86 E8 20 00 00 08 54
					39 00 00 40 00 00 04 B0 00 39 94
					39 00 00 40 00 00 27 94 E2 00 00 00 82 46 24 80 00 00 00 00 FF 90 00 00 01 00 00 00 00 00 00 00 00 00 00 00 00 00 00 00 00 00 00 00 00 00
					39 00 00 40 00 00 04 B0 00 41 94
					39 00 00 40 00 00 07 94 9B 7C 7C 63 FF 90
					39 00 00 00 00 00 03 F0 A5 A5
				];
				qcom,mdss-dsi-loading-effect-3-command = [
				];
				qcom,mdss-dsi-loading-effect-4-command = [
				];
				qcom,mdss-dsi-loading-effect-off-command = [
					39 00 00 40 00 00 03 F0 5A 5A
					39 00 00 40 00 00 04 B0 00 AF 93
					15 00 00 40 00 00 02 93 83
					39 00 00 00 00 00 03 F0 A5 A5
				];
				qcom,mdss-dsi-loading-effect-1-command-state = "dsi_hs_mode";
				qcom,mdss-dsi-loading-effect-2-command-state = "dsi_hs_mode";
				qcom,mdss-dsi-loading-effect-3-command-state = "dsi_hs_mode";
				qcom,mdss-dsi-loading-effect-4-command-state = "dsi_hs_mode";
				qcom,mdss-dsi-loading-effect-off-command-state = "dsi_hs_mode";
				qcom,mdss-dsi-timing-switch-command-state = "dsi_hs_mode";
				qcom,mdss-dsi-on-command-state = "dsi_lp_mode";
				qcom,mdss-dsi-off-command-state = "dsi_hs_mode";
				qcom,mdss-dsi-hbm-on-command-state = "dsi_lp_mode";
				qcom,mdss-dsi-hbm-off-command-state = "dsi_lp_mode";
				qcom,mdss-dsi-bl-16plus-command-state = "dsi_hs_mode";
				qcom,mdss-dsi-bl-3plus-command-state = "dsi_hs_mode";
				qcom,mdss-dsi-temperature-compensation-command-state = "dsi_hs_mode";
				qcom,mdss-dsi-panel-info-switch-page-command-state = "dsi_lp_mode";
				qcom,mdss-dsi-default-switch-page-command-state = "dsi_lp_mode";

				qcom,mdss-dsi-qsync-min-fps-0-command-state = "dsi_hs_mode";
				qcom,mdss-dsi-qsync-min-fps-1-command-state = "dsi_hs_mode";

				qcom,lm-split = <1220 1220>;
				qcom,compression-mode = "dsc";
				qcom,mdss-dsc-encoders = <2>;
				qcom,mdss-dsc-slice-height = <63>;
				qcom,mdss-dsc-slice-width = <1220>;
				qcom,mdss-dsc-slice-per-pkt = <2>;
				qcom,mdss-dsc-bit-per-component = <8>;
				qcom,mdss-dsc-bit-per-pixel = <8>;
				qcom,mdss-dsc-block-prediction-enable;
				qcom,mdss-dsi-panel-id1-command-state = "dsi_lp_mode";
			};
		};
	};
};

&soc {
	dsi_panel_samsung_amf782ec01_2440_2268_dsc_cmd {
		qcom,dsi-display-active;
	};
};

&dsi_panel_samsung_amf782ec01_2440_2268_dsc_cmd {
	qcom,panel-supply-entries = <&oplus_xueying_dsi_panel_pwr_supply>;
	qcom,mdss-dsi-bl-pmic-control-type = "bl_ctrl_dcs";
	qcom,bl-update-flag = "delay_until_first_frame";
	qcom,mdss-dsi-bl-min-level = <1>;
	qcom,mdss-dsi-bl-max-level = <4095>;
	qcom,mdss-brightness-max-level = <4095>;
	oplus,dsi-bl-normal-max-level = <3515>;
	oplus,dsi-brightness-normal-max-level = <3515>;
	oplus,dsi-dc-backlight-threshold = <1960>;
	oplus,dsi-brightness-default-level = <1638>;
	qcom,dynamic-te-gpio = <&tlmm 73 0>;
	qcom,platform-reset-gpio = <&tlmm 133 0>;
	qcom,platform-panel-vout-gpio = <&tlmm 90 0>;
	qcom,platform-panel-vddr-aod-en-gpio = <&pm8550vs_e_gpios 6 0>;
	qcom,mdss-dsi-bl-inverted-dbv;
	qcom,ulps-enabled;

	qcom,dsi-ctrl-num = <0>;
	qcom,dsi-phy-num = <0>;
	qcom,dsi-select-clocks = "pll_byte_clk0", "pll_dsi_clk0";

	/* ofp config */
	oplus,ofp-fp-type = <0x02>;
	oplus,ofp-need-to-wait-data-before-aod-on;

	/* adfr config */
	/* just for qsync enable*/
	qcom,qsync-enable;
	qcom,mdss-dsi-qsync-min-refresh-rate = <24>;
	/*
	** 0st bit: adfr global on/off
	** 1st bit: fakeframe on/off
	** 2st bit: switch on/off
	** 3rd bit: 0:double-TE switch 1:external TE/TP switch
	** 4rd bit: idle mode on/off
	*/
	oplus,adfr-config = <0x11>;  // 0b0001'0001
	oplus,map-index = <3>;  // tmp scheme for sdc

	qcom,mdss-dsi-display-timings {
		timing@sdc_fhd_120 { /* FHD+ 120hz 550Mhz 1100Mbps */
			qcom,mdss-dsi-panel-phy-timings = [00 38 0E 0E 20 28 0E 0E 0D 02 04 00 2C 13];
			qcom,display-topology = <1 1 1>,<2 2 1>;
			qcom,default-topology-index = <1>;
		};
		timing@sdc_fhd_90 { /* FHD+ 90hz 550Mhz 1100Mbps */
			qcom,mdss-dsi-panel-phy-timings = [00 38 0E 0E 20 28 0E 0E 0D 02 04 00 2C 13];
			qcom,display-topology = <1 1 1>,<2 2 1>;
			qcom,default-topology-index = <1>;
		};
		timing@sdc_fhd_60 { /* FHD+ 60hz 550Mhz 1100Mbps */
			qcom,mdss-dsi-panel-phy-timings = [00 38 0E 0E 20 28 0E 0E 0D 02 04 00 2C 13];
			qcom,display-topology = <1 1 1>,<2 2 1>;
			qcom,default-topology-index = <1>;
		};
	};
};
&dsi_panel_samsung_amf782ec01_2440_2268_dsc_cmd {
	qcom,panel_voltage_vddi_name = "vddio";
	qcom,panel_voltage_vddi = <0 1700000 1800000 1900000>;
	qcom,panel_voltage_vddr_name = "vci";
	qcom,panel_voltage_vddr = <1 3000000 3200000 3300000>;
};

&dsi_panel_samsung_amf782ec01_2440_2268_dsc_cmd {
	oplus,color_vivid_status;
	oplus,color_srgb_status;
	oplus,color_oplus_calibrate_status;
	oplus,color_dual_panel_status;
	oplus,color_dual_brightness_status;
	oplus,color_samsung_status;
	oplus,color_loading_status;
	oplus,color_2nit_status;

	/* ESD CONFIG */
	qcom,esd-check-enabled;
	qcom,mdss-dsi-panel-status-check-mode = "reg_read";
	qcom,mdss-dsi-panel-status-command = [
		06 00 00 00 00 00 01 EE
	];
	qcom,mdss-dsi-panel-status-command-state = "dsi_lp_mode";
	qcom,mdss-dsi-panel-status-value = <
		0x00 0x00
	>;
	qcom,mdss-dsi-panel-status-read-length = <2>;
	oplus,mdss-dsi-panel-status-match-modes = <0x00000000>;

	/* serial num config */

	oplus,dsi-serial-number-lock;
	oplus,dsi-serial-number-enabled;
	oplus,dsi-serial-number-switch-page;
	oplus,dsi-serial-number-index= <15>;
	oplus,dsi-serial-number-reg= <0xD8>;
	oplus,dsi-serial-number-read-count= <22>;
};

